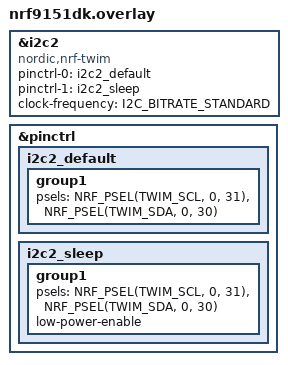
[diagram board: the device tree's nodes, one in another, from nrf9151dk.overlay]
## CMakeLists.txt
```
cmake_minimum_required(VERSION 3.20.0)
find_package(Zephyr REQUIRED HINTS $ENV{ZEPHYR_BASE})

project(test_i2c)

target_sources(app PRIVATE src/main.c)
```

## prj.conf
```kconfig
CONFIG_I2C=y
CONFIG_I2C_NRFX=y
CONFIG_MAIN_STACK_SIZE=2048
```

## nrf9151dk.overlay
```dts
&i2c2 {
    status = "okay";
    compatible = "nordic,nrf-twim";
    pinctrl-0 = <&i2c2_default>;
    pinctrl-1 = <&i2c2_sleep>;
    pinctrl-names = "default", "sleep";
    clock-frequency = <I2C_BITRATE_STANDARD>; // 100kHz
};

&pinctrl {
    i2c2_default: i2c2_default {
        group1 {
            psels = <NRF_PSEL(TWIM_SCL, 0, 31)>, <NRF_PSEL(TWIM_SDA, 0, 30)>;
        };
    };

    i2c2_sleep: i2c2_sleep {
        group1 {
            psels = <NRF_PSEL(TWIM_SCL, 0, 31)>, <NRF_PSEL(TWIM_SDA, 0, 30)>;
            low-power-enable;
        };
    };
};
```

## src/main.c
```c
#include <zephyr/kernel.h>
#include <zephyr/device.h>
#include <zephyr/drivers/i2c.h>
#include <zephyr/sys/printk.h>

#define I2C_NODE DT_NODELABEL(i2c2)
#define I2C_ADDR 0x68  // Dirección del esclavo I2C (ej: MPU6050)

int main(void)
{
    const struct device *i2c_dev = DEVICE_DT_GET(I2C_NODE);

    if (!device_is_ready(i2c_dev)) {
        printk("I2C: Device not ready.\n");
        return;
    }

    uint8_t whoami_reg = 0x75;
    uint8_t whoami_val;

    int ret = i2c_write_read(i2c_dev, I2C_ADDR, &whoami_reg, sizeof(whoami_reg),
                             &whoami_val, sizeof(whoami_val));

    if (ret == 0) {
        printk("WHOAMI: 0x%02X\n", whoami_val);
    } else {
        printk("I2C read failed: %d\n", ret);
    }

    return 0;   
}
```
